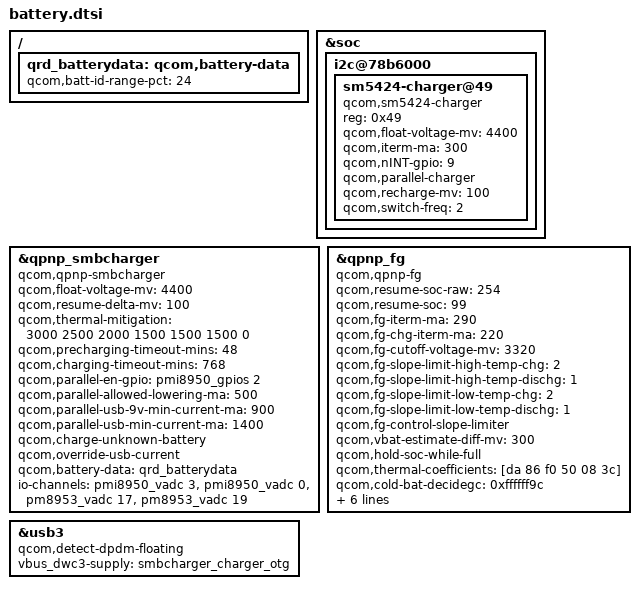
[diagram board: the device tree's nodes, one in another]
/ {
	qrd_batterydata: qcom,battery-data {
		qcom,batt-id-range-pct = <24>;
		#include "batterydata/msm8953-batterydata-m1721.dtsi"
	};

};

&soc {
	i2c@78b6000 {
        status = "ok";

        sm5424-charger@49 {
            compatible = "qcom,sm5424-charger";
            reg = <0x49>;
            status = "ok";
            
            qcom,float-voltage-mv = <4400>;
            qcom,iterm-ma = <300>;
            qcom,nINT-gpio = <9>;
            qcom,parallel-charger;
            qcom,recharge-mv = <100>;
            qcom,switch-freq = <2>;
        };
    };
};

&qpnp_smbcharger {
	compatible = "qcom,qpnp-smbcharger";

    qcom,float-voltage-mv = <4400>;
	qcom,resume-delta-mv = <100>;
    qcom,thermal-mitigation = <3000 2500 2000 1500 1500 1500 0>;
    qcom,precharging-timeout-mins = <48>;
    qcom,charging-timeout-mins = <768>;
    qcom,parallel-en-gpio = <&pmi8950_gpios 2 0>;
    qcom,parallel-allowed-lowering-ma = <500>;
    qcom,parallel-usb-9v-min-current-ma = <900>;
    qcom,parallel-usb-min-current-ma = <1400>;
	qcom,charge-unknown-battery;
    qcom,override-usb-current;
    qcom,battery-data = <&qrd_batterydata>;
    io-channels = <&pmi8950_vadc 3>, 
    			<&pmi8950_vadc 0>, 
    			<&pm8953_vadc 17>, 
    			<&pm8953_vadc 19>; 
    io-channel-names = "vchg_sns", "vusbin", "usbchg_temp", "board_temp";
 
	/delete-property/ qcom,autoadjust-vfloat;
	/delete-property/ qcom,external-typec;
	/delete-property/ qcom,typec-psy-name;
	/delete-property/ qcom,vchg_sns-vadc;
	/delete-property/ qcom,vusbin-vadc;
	/delete-property/ qcom,usbchg_temp-vadc;
	/delete-property/ qcom,board_temp-vadc;
	/delete-property/ qcom,vchg-adc-channel-id;
	/delete-property/ qcom,vusbin-adc-channel-id;
	/delete-property/ qcom,usbchg_temp-adc-channel-id;
	/delete-property/ qcom,board_temp-adc-channel-id;
    status = "okay";
};

&qpnp_fg {
	compatible = "qcom,qpnp-fg";

    qcom,resume-soc-raw = <254>;
    qcom,resume-soc = <99>;
    qcom,fg-iterm-ma = <290>;
    qcom,fg-chg-iterm-ma = <220>;
    qcom,fg-cutoff-voltage-mv = <3320>;
    qcom,fg-slope-limit-high-temp-chg = <2>;
    qcom,fg-slope-limit-high-temp-dischg = <1>;
    qcom,fg-slope-limit-low-temp-chg = <2>;
    qcom,fg-slope-limit-low-temp-dischg = <1>;
    qcom,fg-control-slope-limiter;
    qcom,vbat-estimate-diff-mv = <300>;
    qcom,hold-soc-while-full;
    qcom,thermal-coefficients = [da 86 f0 50 08 3c];
    qcom,cold-bat-decidegc = <0xffffff9c>; /* -99 */
    qcom,cool-bat-decidegc = <0>;
    qcom,warm-bat-decidegc = <550>;
    qcom,hot-bat-decidegc = <550>;
    qcom,bad-battery-detection-enable;
    qcom,ext-sense-type;
    qcom,battery-data = <&qrd_batterydata>;
    status = "okay";
};

&usb3 {
	qcom,detect-dpdm-floating;
	vbus_dwc3-supply = <&smbcharger_charger_otg>;
};
